AUTOSAR XML (schema 3-1-5)
standard types defined: Boolean, SInt8, UInt8, SInt16, UInt16, UInt32, SInt32, Float
package /rte_simple_lib/CalculatorKit
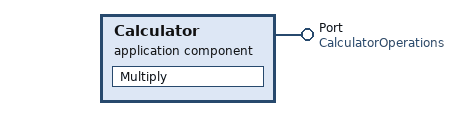
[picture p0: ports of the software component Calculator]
  application software component type Calculator
    provide port Port: provided-interface=CalculatorOperations
  internal behavior CalculatorBehavior: component=Calculator
    operation invoked event InvokeCalculator: start-on-event=Multiply, operation=Port.Multiply
    runnable Multiply: can-be-invoked-concurrently=true
  swc implementation CalculatorImplementation: behavior=CalculatorBehavior
package /rte_simple_lib/Interfaces
  client server interface CalculatorOperations
    operation Multiply
      arg arg1: type=UInt8, direction=IN
      arg arg2: type=UInt8, direction=IN
      arg result: type=UInt16, direction=OUT
  sender receiver interface ArgumentIf
    data arg1: type=UInt8
    data arg2: type=UInt8
  sender receiver interface ResultIf
    data result: type=UInt16
package /rte_simple_lib/TesterKit
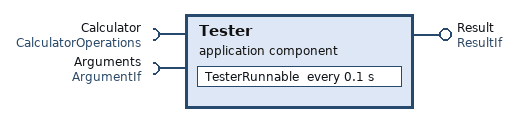
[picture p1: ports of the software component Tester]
  application software component type Tester
    require port Calculator: required-interface=CalculatorOperations
    require port Arguments: required-interface=ArgumentIf
    provide port Result: provided-interface=ResultIf
  internal behavior TesterBehavior: component=Tester
    timing event StepTester: start-on-event=TesterRunnable, period=0.1
    runnable TesterRunnable: can-be-invoked-concurrently=true
      data read access ReadArg1: data-element=Arguments.arg1
      data read access ReadArg2: data-element=Arguments.arg2
      data write access WriteResult: data-element=Result.result
      sync call CallCalculator: operation=Calculator.Multiply
  swc implementation TesterImplementation: behavior=TesterBehavior
package /rte_simple_lib/LoggerKit
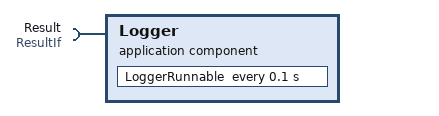
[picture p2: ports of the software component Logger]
  application software component type Logger
    require port Result: required-interface=ResultIf
  internal behavior LoggerBehavior: component=Logger
    timing event StepLogger: start-on-event=LoggerRunnable, period=0.1
    runnable LoggerRunnable: can-be-invoked-concurrently=true
      data read access ReadResult: data-element=Result.result
  swc implementation LoggerImplementation: behavior=LoggerBehavior
package /rte_simple_lib/Logger2Kit
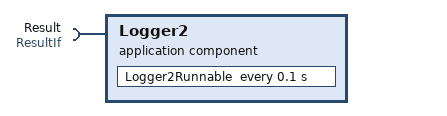
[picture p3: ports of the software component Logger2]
  application software component type Logger2
    require port Result: required-interface=ResultIf
  internal behavior Logger2Behavior: component=Logger2
    timing event StepLogger2: start-on-event=Logger2Runnable, period=0.1
    runnable Logger2Runnable: can-be-invoked-concurrently=true
      data read access ReadResult: data-element=Result.result
  swc implementation Logger2Implementation: behavior=Logger2Behavior
